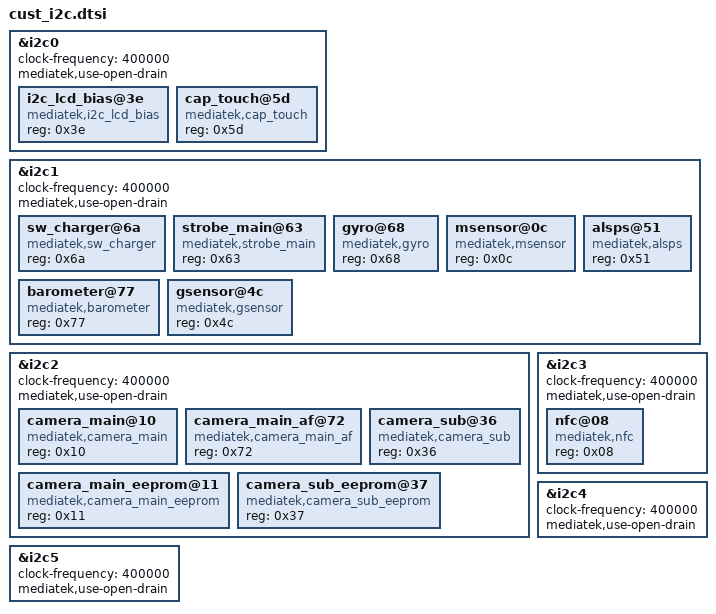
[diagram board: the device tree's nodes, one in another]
/*
 * Generated by MTK SP DrvGen Version: 3.5.160809 for MT6739.
 * 2019-11-11 10:46:44
 * Do Not Modify The File.
 * Copyright Mediatek Inc. (c) 2016.
*/

/*************************
 * I2C DTSI File
*************************/

&i2c0 {
	#address-cells = <1>;
	#size-cells = <0>;
	clock-frequency = <400000>;
	mediatek,use-open-drain;
	i2c_lcd_bias@3e {
		compatible = "mediatek,i2c_lcd_bias";
		reg = <0x3e>;
		status = "okay";
	};

	cap_touch@5d {
		compatible = "mediatek,cap_touch";
		reg = <0x5d>;
		status = "okay";
	};

};

&i2c1 {
	#address-cells = <1>;
	#size-cells = <0>;
	clock-frequency = <400000>;
	mediatek,use-open-drain;
	sw_charger@6a {
		compatible = "mediatek,sw_charger";
		reg = <0x6a>;
		status = "okay";
	};

	strobe_main@63 {
		compatible = "mediatek,strobe_main";
		reg = <0x63>;
		status = "okay";
	};

	gyro@68 {
		compatible = "mediatek,gyro";
		reg = <0x68>;
		status = "okay";
	};

	msensor@0c {
		compatible = "mediatek,msensor";
		reg = <0x0c>;
		status = "okay";
	};

	barometer@77 {
		compatible = "mediatek,barometer";
		reg = <0x77>;
		status = "okay";
	};

	gsensor@4c {
		compatible = "mediatek,gsensor";
		reg = <0x4c>;
		status = "okay";
	};

	alsps@51 {
		compatible = "mediatek,alsps";
		reg = <0x51>;
		status = "okay";
	};

};

&i2c2 {
	#address-cells = <1>;
	#size-cells = <0>;
	clock-frequency = <400000>;
	mediatek,use-open-drain;
	camera_main@10 {
		compatible = "mediatek,camera_main";
		reg = <0x10>;
		status = "okay";
	};

	camera_main_af@72 {
		compatible = "mediatek,camera_main_af";
		reg = <0x72>;
		status = "okay";
	};

	camera_sub@36 {
		compatible = "mediatek,camera_sub";
		reg = <0x36>;
		status = "okay";
	};

	camera_main_eeprom@11 {
		compatible = "mediatek,camera_main_eeprom";
		reg = <0x11>;
		status = "okay";
	};

	camera_sub_eeprom@37 {
		compatible = "mediatek,camera_sub_eeprom";
		reg = <0x37>;
		status = "okay";
	};

};

&i2c3 {
	#address-cells = <1>;
	#size-cells = <0>;
	clock-frequency = <400000>;
	mediatek,use-open-drain;
	nfc@08 {
		compatible = "mediatek,nfc";
		reg = <0x08>;
		status = "okay";
	};

};

&i2c4 {
	#address-cells = <1>;
	#size-cells = <0>;
	clock-frequency = <400000>;
	mediatek,use-open-drain;
};

&i2c5 {
	#address-cells = <1>;
	#size-cells = <0>;
	clock-frequency = <400000>;
	mediatek,use-open-drain;
};

